# NUC123AE_v1 register map
File version: 1.0
NUC123AE_v1 SVD file
Registers are 32-bit, read-write, reset 0x0 unless marked. A register's access mark holds for its fields unless they carry their own. Offsets are from the block's base; lines under a group give offsets from that group; [hi:lo] are bit positions; {n}, {i} and the like mark numbered series; 'fields as' and 'values as' point back to an identical list; <NAME> marks a mode.

## Memory map
0x40004000 WDT size 0x8 — WDT Register Map
0x40004100 WWDT size 0x10 — WWDT Register Map
0x40010000 TMR01 blocks up to offset 0x3C — TMR Register Map
0x40020000 I2C0 blocks up to offset 0x44 — I2C Register Map
0x40030000 SPI0 blocks up to offset 0x48 — SPI Register Map
0x40034000 SPI1 blocks up to offset 0x48 — SPI Register Map
0x40040000 PWMA blocks up to offset 0xD4 — PWMA Register Map
0x40050000 UART0 size 0x34 — UART Register Map
0x40060000 USB blocks up to offset 0x580 — USB Register Map
0x400E0000 ADC blocks up to offset 0x44 — ADC Register Map
0x40100000 PS2 size 0x20 — PS2 Register Map
0x40110000 TMR23 blocks up to offset 0x3C — TMR Register Map
0x40120000 I2C1 blocks up to offset 0x44 — I2C Register Map
0x40130000 SPI2 blocks up to offset 0x48 — SPI Register Map
0x40150000 UART1 size 0x34 — UART Register Map
0x401A0000 I2S size 0x18 — I2S Register Map
0x50000000 GCR blocks up to offset 0x15C — GCR Register Map
0x50000200 CLK blocks up to offset 0x30 — CLK Register Map
0x50000300 INT size 0x88 — INT Register Map
0x50004000 GP blocks up to offset 0x350 — GP Register Map
0x50008000 PDMA_ch0 blocks up to offset 0x84 — PDMA Register Map
0x50008100 PDMA_ch1 blocks up to offset 0x84 — PDMA Register Map
0x50008200 PDMA_ch2 blocks up to offset 0x84 — PDMA Register Map
0x50008300 PDMA_ch3 blocks up to offset 0x84 — PDMA Register Map
0x50008400 PDMA_ch4 blocks up to offset 0x84 — PDMA Register Map
0x50008500 PDMA_ch5 blocks up to offset 0x84 — PDMA Register Map
0x50008E00 CRC blocks up to offset 0x8C — PDMA Register Map
0x50008F00 DMA_GCR size 0x14 — PDMA Register Map
0x5000C000 FMC blocks up to offset 0x44 — FMC Register Map
0xE000E000 SCS blocks up to offset 0xD24 — SCS Register Map

## INT — INT Register Map
Base 0x50000300
{0x0+4i} IRQ{i}_SRC ro reset not defined (i=0..31) — IRQ{i} (BOD) interrupt source identity
  [3:0] INT_SRC — Interrupt Source. Define the interrupt sources for interrupt event.
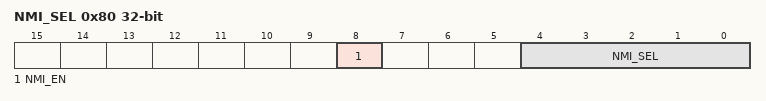
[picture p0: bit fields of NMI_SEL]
0x80 NMI_SEL — NMI Source Interrupt Select Control Register
  [8] NMI_EN — NMI Interrupt Enable
    0=NMI interrupt Disabled; 1=NMI interrupt Enabled
  [4:0] NMI_SEL — NMI Interrupt Source Selection. The NMI interrupt to Cortex-M0 can be selected from one of the peripheral interrupt by setting NMI_SEL.
0x84 MCU_IRQ — MCU Interrupt Request Source Register
  [31:0] MCU_IRQ — MCU IRQ Source Register. The MCU_IRQ collects all the interrupts from the peripherals and generates the synchronous interrupt to Cortex-M0. There are two modes to generate interrupt to Cortex-M0, Normal mode. The MCU_IRQ collects all interrupts from each peripheral and synchronizes them and then interrupts the Cortex-M0. When the MCU_IRQ[n] is 0: Set MCU_IRQ[n] 1 will generate an interrupt to Cortex_M0 NVIC[n]. When the MCU_IRQ[n] is 1 (mean an interrupt is assert), setting 1 to the MCU_bit[n] will clear the interrupt and setting MCU_IRQ[n] 0 has no effect.

## I2C0 — I2C Register Map
Base 0x40020000
Same registers: I2C1 0x40120000
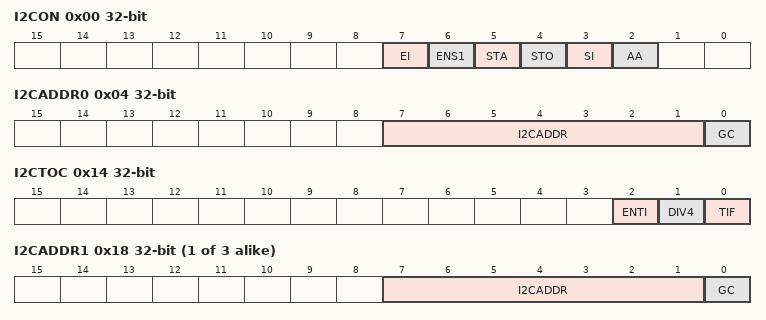
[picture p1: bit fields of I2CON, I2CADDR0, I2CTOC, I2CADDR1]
0x00 I2CON — I2C Control Register
  [7] EI — Enable Interrupt
    0=I2C interrupt Disabled; 1=I2C interrupt Enabled
  [6] ENS1 — I2C Controller Enable Bit
    0=Disabled; 1=Enabled
  [5] STA — I2C START Control Bit. Setting STA to logic 1 to enter Master mode, the I2C hardware sends a START or repeat START condition to bus when the bus is free.
  [4] STO — I2C STOP Control Bit. In Master mode, setting STO to transmit a STOP condition to bus then I2C hardware will check the bus condition if a STOP condition is detected this bit will be cleared by hardware automatically. In a Slave mode, setting STO resets I2C hardware to the defined "not addressed" Slave mode. This means it is NO LONGER in the slave receiver mode to receive data from the master transmit device.
  [3] SI — I2C Interrupt Flag. When a new I2C state is present in the I2CSTATUS register, the SI flag is set by hardware, and if bit EI (I2CON [7]) is set, the I2C interrupt is requested. SI must be cleared by software. Clear SI is by writing 1 to this bit.
  [2] AA — Assert Acknowledge Control Bit
0x04 I2CADDR0 — I2C Slave Address Register0
  [7:1] I2CADDR — I2C Address Register. The content of this register is irrelevant when I2C is in Master mode. In Slave mode, the seven most significant bits must be loaded with the chip's own address. The I2C hardware will react if either of the addresses is matched.
  [0] GC — General Call Function
    0=General Call function Disabled; 1=General Call function Enabled
0x08 I2CDAT — I2C Data Register
  [7:0] I2CDAT — I2C Data Register. Bit [7:0] is located with the 8-bit transferred data of I2C serial port.
0x0C I2CSTATUS ro reset 0xF8
  [7:0] I2CSTATUS — I2C Status Register. The status register of I2C:
0x10 I2CLK — I2C Clock Divided Register
  [7:0] I2CLK — I2C clock divided Register
0x14 I2CTOC — I2C Time-Out Counter Register
  [2] ENTI — Time-out Counter Enable/Disable. When Enabled, the 14-bit time-out counter will start counting when SI is cleared. Setting the flag SI to high will reset counter and re-start counting up after SI is cleared.
    0=Disabled; 1=Enabled
  [1] DIV4 — Time-out Counter Input Clock Divided by 4. When Enabled, the time-out period is extend 4 times.
    0=Disabled; 1=Enabled
  [0] TIF — Time-Out Flag
    0=Software can clear the flag; 1=Time-out flag is set by H/W. It can interrupt CPU
{0x14+4i} I2CADDR{i} (i=1..3) — I2C Slave Address Register{i}
  fields as I2CADDR0
{0x24+4i} I2CADM{i} (i=0..3) — I2C Slave Address Mask Register{i}
  [7:1] I2CADM — I2C Address Mask Register. I2C bus controllers support multiple address recognition with four address mask register. When the bit in the address mask register is set to one, it means the received corresponding address bit is don't-care. If the bit is set to zero, it means the received corresponding register bit should be exact the same as address register.
    0=Mask Disabled (the received corresponding register bit should be exactly the same as address register.); 1=Mask Enabled (the received corresponding address bit is don't care.)
0x3C I2CWKUPCON — I2C Wake-up Control Register
  [0] WKUPEN — I2C Wake-up Function Enable
    0=I2C wake-up function Disabled; 1=I2C wake-up function Enabled
0x40 I2CWKUPSTS ro — I2C Wake-up Status Register
  [0] WKUPIF — Wake-up Interrupt Flag. Software can write one to clear this flag
    0=Wake-up flag inactive; 1=Wake-up flag active
